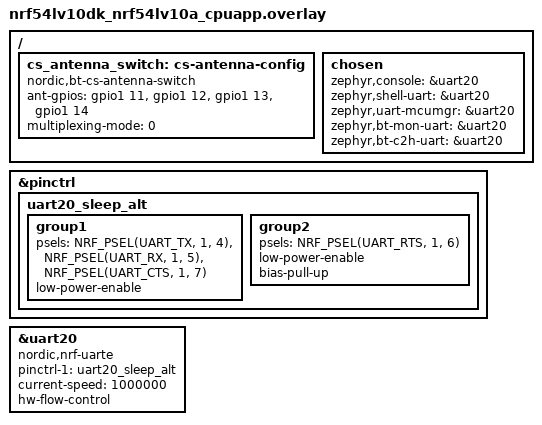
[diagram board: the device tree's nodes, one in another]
/* SPDX-License-Identifier: Apache-2.0 */

/ {
	cs_antenna_switch: cs-antenna-config {
		status = "okay";
		compatible = "nordic,bt-cs-antenna-switch";
		ant-gpios = <&gpio1 11 (GPIO_ACTIVE_HIGH)>,
			<&gpio1 12 (GPIO_ACTIVE_HIGH)>,
			<&gpio1 13 (GPIO_ACTIVE_HIGH)>,
			<&gpio1 14 (GPIO_ACTIVE_HIGH)>;
		multiplexing-mode = <0>;
	};
};

// NCSDK-36190: remove the workaround when hci_uart_async sample is fixed
&pinctrl {
    uart20_sleep_alt: uart20_sleep_alt {
      group1 {
        psels = <NRF_PSEL(UART_TX, 1, 4)>,
          <NRF_PSEL(UART_RX, 1, 5)>,
          <NRF_PSEL(UART_CTS, 1, 7)>;
        low-power-enable;
      };
      group2 {
        psels = <NRF_PSEL(UART_RTS, 1, 6)>;
        low-power-enable;
        bias-pull-up;
      };
    };
};

&uart20 {
	compatible = "nordic,nrf-uarte";
    pinctrl-1 = <&uart20_sleep_alt>;
	current-speed = <1000000>;
	status = "okay";
	hw-flow-control;
};

/ {
	chosen {
		zephyr,console = &uart20;
		zephyr,shell-uart = &uart20;
		zephyr,uart-mcumgr = &uart20;
		zephyr,bt-mon-uart = &uart20;
		zephyr,bt-c2h-uart = &uart20;
	};
};
